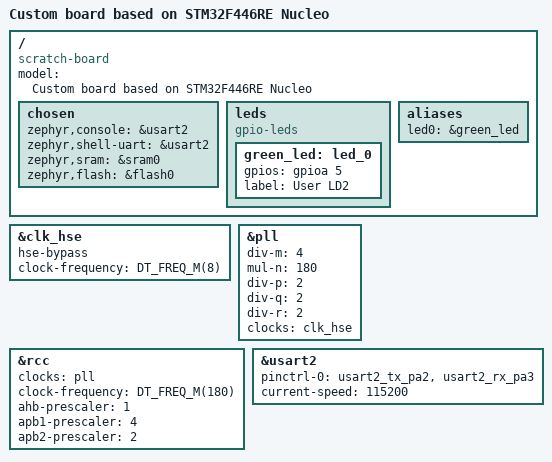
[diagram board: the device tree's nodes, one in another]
/dts-v1/;
#include <st/f4/stm32f446Xe.dtsi>
#include <st/f4/stm32f446r(c-e)tx-pinctrl.dtsi>
#include <zephyr/dt-bindings/gpio/gpio.h>

/ {
	model = "Custom board based on STM32F446RE Nucleo";
	compatible = "scratch-board";

	chosen {
		zephyr,console = &usart2;
		zephyr,shell-uart = &usart2;
		zephyr,sram = &sram0;
		zephyr,flash = &flash0;
	};

	leds {
		compatible = "gpio-leds";
		green_led: led_0 {
			gpios = <&gpioa 5 GPIO_ACTIVE_HIGH>;
			label = "User LD2";
		};
	};

	aliases {
		led0 = &green_led;
	};
};

&clk_hse {
	hse-bypass;
	clock-frequency = <DT_FREQ_M(8)>; /* 8 MHz from ST-LINK MCO */
	status = "okay";
};

&pll {
	div-m = <4>;
	mul-n = <180>;
	div-p = <2>;
	div-q = <2>;
	div-r = <2>;
	clocks = <&clk_hse>;
	status = "okay";
};

&rcc {
	clocks = <&pll>;
	clock-frequency = <DT_FREQ_M(180)>;
	ahb-prescaler = <1>;
	apb1-prescaler = <4>;
	apb2-prescaler = <2>;
};

/* USART2 is wired to the ST-LINK virtual COM port (PA2 = TX, PA3 = RX) */
&usart2 {
	pinctrl-0 = <&usart2_tx_pa2 &usart2_rx_pa3>;
	pinctrl-names = "default";
	current-speed = <115200>;
	status = "okay";
};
